# ATSAM4LC2A device description
Architecture: CORTEX-M4; Family: SAM4; Series: SAM4L
Registers are 32-bit, read-write, reset 0x0 unless marked. A register's access mark holds for its fields unless they carry their own. Offsets are from the block's base; [hi:lo] are bit positions; 'fields as' and 'values as' point back to an identical list.

## AST — Asynchronous Timer
Instances: AST 0x400F0800
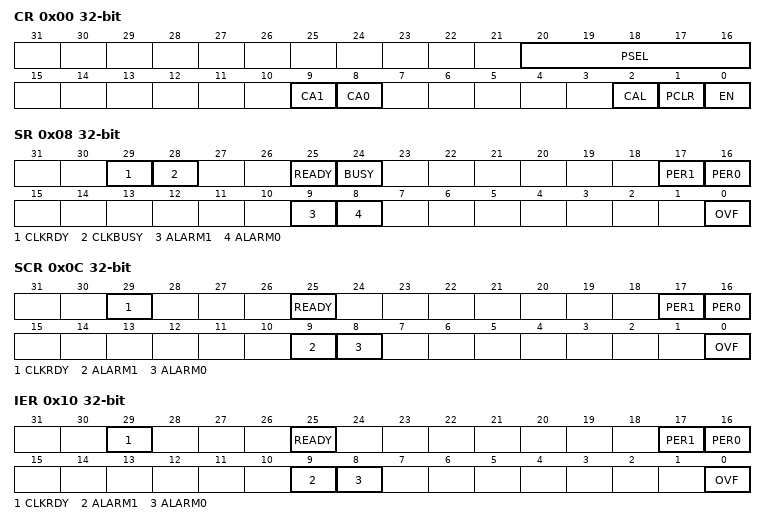
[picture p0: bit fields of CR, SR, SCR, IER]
0x00 CR — Control Register
  [20:16] PSEL — Prescaler Select
  [9] CA1 — Clear on Alarm 1
  [8] CA0 — Clear on Alarm 0
  [2] CAL — Calendar mode
  [1] PCLR — Prescaler Clear
  [0] EN — Enable
    0=The AST is disabled; 1=The AST is enabled
0x04 CV — Counter Value
  [31:0] VALUE — AST Value
0x08 SR ro — Status Register
  [29] CLKRDY — Clock Ready
  [28] CLKBUSY — Clock Busy
    0=The clock is ready and can be changed; 1=CEN has been written and the clock is busy
  [25] READY — AST Ready
  [24] BUSY — AST Busy
    0=The AST accepts writes to CV, WER, DTR, SCR, AR, PIR and CR; 1=The AST is busy and will discard writes to CV, WER, DTR, SCR, AR, PIR and CR
  [17] PER1 — Periodic 1
  [16] PER0 — Periodic 0
  [9] ALARM1
  [8] ALARM0
  [0] OVF — Overflow
0x0C SCR wo (atomic clear of SR) — Status Clear Register
  [29] CLKRDY — Clock Ready
  [25] READY — AST Ready
  [17] PER1 — Periodic 1
  [16] PER0 — Periodic 0
  [9] ALARM1
  [8] ALARM0
  [0] OVF — Overflow
0x10 IER wo (atomic set of IMR) — Interrupt Enable Register
  [29] CLKRDY — Clock Ready
    0=No effect; 1=Enable interrupt
  [25] READY — AST Ready
    0=No effect; 1=Enable interrupt
  [17] PER1 — Periodic 1
    0=No effect; 1=Enable interrupt
  [16] PER0 — Periodic 0
    0=No effect; 1=Enable interrupt
  [9] ALARM1
    0=No effect; 1=Enable interrupt
  [8] ALARM0
    0=No effect; 1=Enable interrupt
  [0] OVF — Overflow
    0=No effect; 1=Enable Interrupt
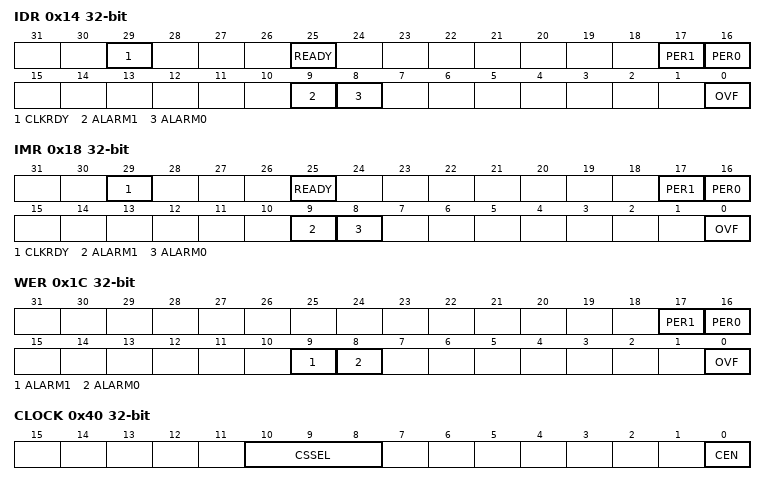
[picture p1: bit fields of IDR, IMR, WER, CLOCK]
0x14 IDR wo (atomic clear of IMR) — Interrupt Disable Register
  [29] CLKRDY — Clock Ready
    0=No effect; 1=Disable interrupt
  [25] READY — AST Ready
    0=No effect; 1=Disable interrupt
  [17] PER1 — Periodic 1
    0=No effect; 1=Disable interrupt
  [16] PER0 — Periodic 0
    0=No effet; 1=Disalbe interrupt
  [9] ALARM1
    0=No effect; 1=Disable interrupt
  [8] ALARM0
    0=No effect; 1=Disable interrupt
  [0] OVF — Overflow
    0=No effect; 1=Disable Interrupt
0x18 IMR ro — Interrupt Mask Register
  [29] CLKRDY — Clock Ready
    0=Interrupt is disabled; 1=Interrupt is enabled
  [25] READY — AST Ready
    0=Interrupt is disabled; 1=Interrupt is enabled
  [17] PER1 — Periodic 1
    0=Interrupt is disabled; 1=Interrupt is enabled
  [16] PER0 — Periodic 0
    0=Interrupt is disabled; 1=Interrupt is enabled
  [9] ALARM1
    0=Interrupt is disabled; 1=Interrupt is enabled
  [8] ALARM0
    0=Interupt is disabled; 1=Interrupt is enabled
  [0] OVF — Overflow
    0=Interrupt is disabled; 1=Interrupt is enabled
0x1C WER — Wake Enable Register
  [all] fields
    0=The corresponing event will not wake up the CPU from sleep mode; 1=The corresponding event will wake up the CPU from sleep mode
  [17] PER1 — Periodic 1
  [16] PER0 — Periodic 0
  [9] ALARM1
  [8] ALARM0
  [0] OVF — Overflow
0x20 AR0 — Alarm Register 0
  [31:0] VALUE — Alarm Value
0x24 AR1 — Alarm Register 1
  [31:0] VALUE — Alarm Value
0x30 PIR0 — Periodic Interval Register 0
  [4:0] INSEL — Interval Select
0x34 PIR1 — Periodic Interval Register 1
  [4:0] INSEL — Interval Select
0x40 CLOCK — Clock Control Register
  [10:8] CSSEL — Clock Source Selection
    0=SLOWCLOCK; 1=32KHZCLK (32 kHz clock); 2=PBCLOCK; 3=GCLK (Generic clock); 4=1KHZCLK (1kHz clock from 32 kHz oscillator)
  [0] CEN — Clock Enable
    0=The clock is disabled; 1=The clock is enabled
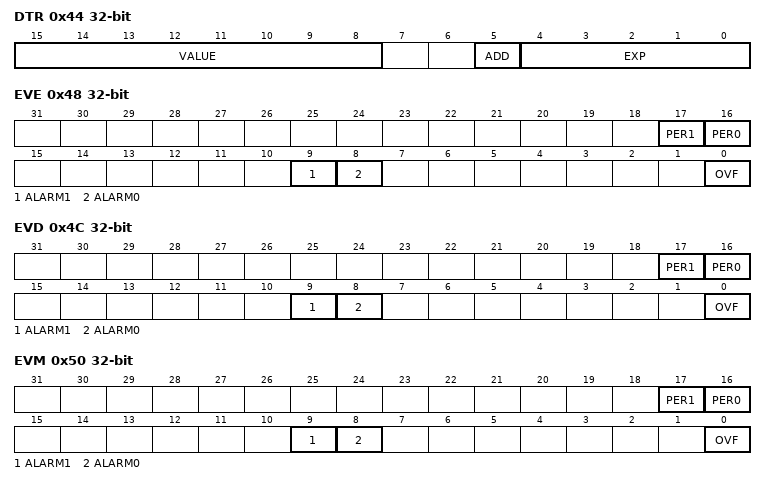
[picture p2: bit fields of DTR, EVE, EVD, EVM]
0x44 DTR — Digital Tuner Register
  [15:8] VALUE, [5] ADD, [4:0] EXP
0x48 EVE wo (atomic set of EVM) — Event Enable Register
  [17] PER1 — Periodic 1
  [16] PER0 — Perioidc 0
  [9] ALARM1
  [8] ALARM0
  [0] OVF — Overflow
0x4C EVD wo (atomic clear of EVM) — Event Disable Register
  fields as EVE
0x50 EVM ro — Event Mask Register
  fields as EVE
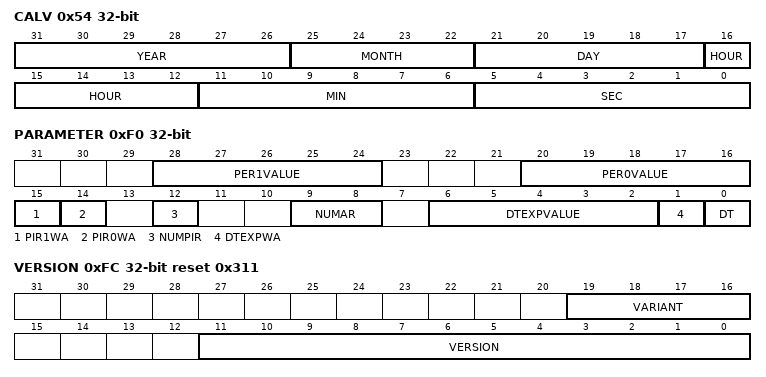
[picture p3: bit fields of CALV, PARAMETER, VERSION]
0x54 CALV — Calendar Value
  [31:26] YEAR
  [25:22] MONTH
  [21:17] DAY
  [16:12] HOUR
  [11:6] MIN — Minute
  [5:0] SEC — Second
0xF0 PARAMETER ro reset not defined
  [28:24] PER1VALUE — Periodic Interval 1 Value
  [20:16] PER0VALUE — Periodic Interval 0 Value
  [15] PIR1WA — Periodic Interval 1 Writeable
    0=Writes to PIR1 will be discarded; 1=PIR1 can be written
  [14] PIR0WA — Periodic Interval 0 Writeable
    0=Periodic alarm prescaler 0 tapping is a constant value. Writes to INSEL bitfield in PIR0 will be discarded.; 1=Periodic alarm prescaler 0 tapping is chosen by writing to INSEL bitfield in PIR0
  [12] NUMPIR — Number of periodic comparators
    0=ONE (One periodic comparator); 1=TWO (Two periodic comparators)
  [9:8] NUMAR — Number of alarm comparators
    0=ZERO (No alarm comparators); 1=ONE (One alarm comparator); 2=TWO (Two alarm comparators)
  [6:2] DTEXPVALUE — Digital Tuner Exponent Value
  [1] DTEXPWA — Digital Tuner Exponent Writeable
    0=Digital tuner exponent is a constant value. Writes to EXP bitfield in DTR will be discarded.; 1=Digital tuner exponent is chosen by writing to EXP bitfield in DTR
  [0] DT — Digital Tuner
    0=OFF (Digital tuner off); 1=ON (Digital tuner on)
0xFC VERSION ro reset 0x311
  [19:16] VARIANT — Variant Number
  [11:0] VERSION — Version Number

## Notices in the file
Copyright (c) 2016 Atmel Corporation,
a wholly owned subsidiary of Microchip Technology Inc.
Licensed under the Apache License, Version 2.0 (the "License");
you may not use this file except in compliance with the License.
You may obtain a copy of the Licence at
http://www.apache.org/licenses/LICENSE-2.0
Unless required by applicable law or agreed to in writing, software
distributed under the License is distributed on an "AS IS" BASIS,
WITHOUT WARRANTIES OR CONDITIONS OF ANY KIND, either express or implied.
See the License for the specific language governing permissions and
limitations under the License.
